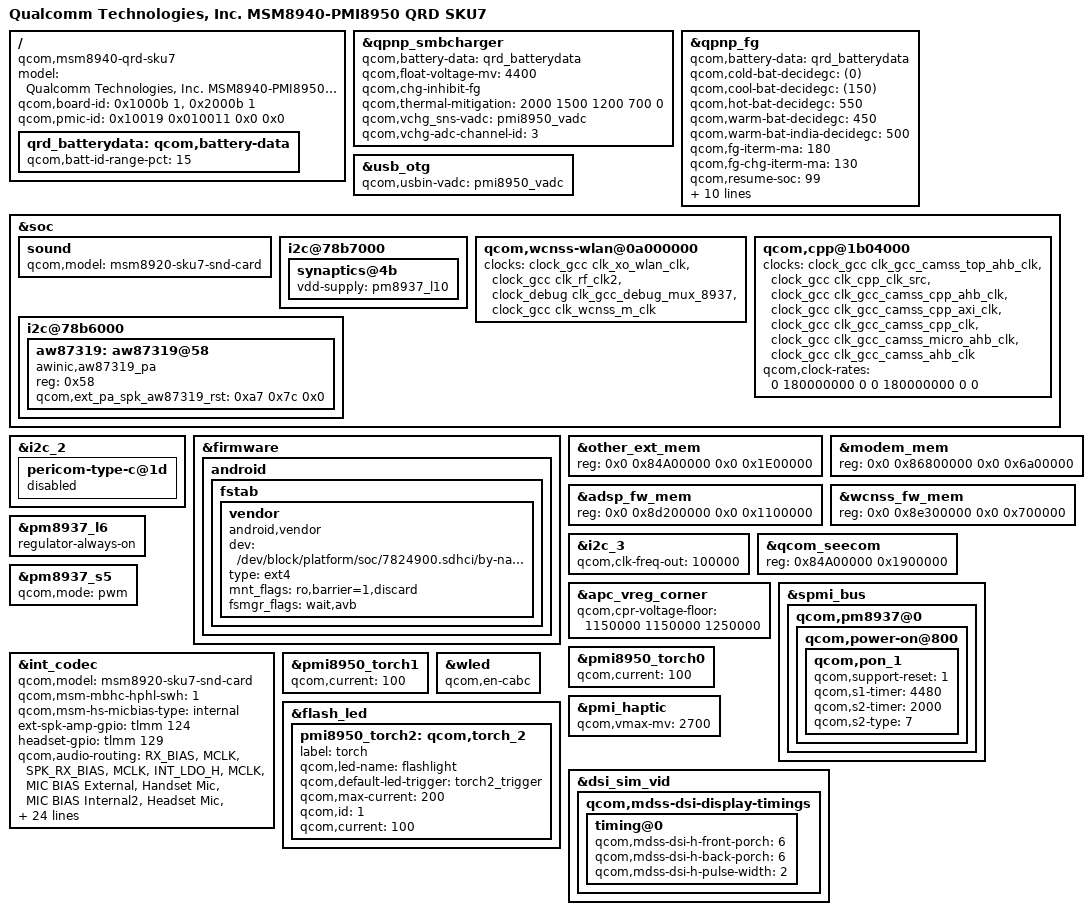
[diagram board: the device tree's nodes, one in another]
/*
 * Copyright (c) 2016, The Linux Foundation. All rights reserved.
 * Copyright (C) 2018 XiaoMi, Inc.
 *
 * This program is free software; you can redistribute it and/or modify
 * it under the terms of the GNU General Public License version 2 and
 * only version 2 as published by the Free Software Foundation.
 *
 * This program is distributed in the hope that it will be useful,
 * but WITHOUT ANY WARRANTY; without even the implied warranty of
 * MERCHANTABILITY or FITNESS FOR A PARTICULAR PURPOSE.  See the
 * GNU General Public License for more details.
 */

/dts-v1/;

#include "msm8940.dtsi"
#include "msm8937-pmi8950-qrd-sku1_S88536AA2.dtsi"
#include "msm8940-pinctrl.dtsi"

/ {
	model = "Qualcomm Technologies, Inc. MSM8940-PMI8950 QRD SKU7";
	compatible = "qcom,msm8940-qrd-sku7", "qcom,msm8940-qrd",
			"qcom,msm8940", "qcom,qrd";
	qcom,board-id= <0x1000b 1>, <0x2000b 1>;
	qcom,pmic-id = <0x10019 0x010011 0x0 0x0>;
};

/ {
	qrd_batterydata: qcom,battery-data {
		qcom,batt-id-range-pct = <15>;
		#include "batterydata-qrd-Desay-4v4-4100mah.dtsi"
		#include "batterydata-qrd-Atl-4v4-4100mah.dtsi"
		#include "batterydata-qrd-Coslight-4v4-4100mah.dtsi"
		#include "batterydata-qrd-Default-4v4-4100mah.dtsi"
	};
};

&qpnp_smbcharger { 
	qcom,battery-data = <&qrd_batterydata>;
	qcom,float-voltage-mv = <4400>;
	qcom,chg-inhibit-fg;
	qcom,thermal-mitigation = <2000 1500 1200 700 0>;
	status = "okay";
	qcom,vchg_sns-vadc = <&pmi8950_vadc>;
	qcom,vchg-adc-channel-id = <3>;

	/delete-property/ qcom,autoadjust-vfloat;
        /delete-property/ dpdm-supply;
};

&qpnp_fg { 
	qcom,battery-data = <&qrd_batterydata>;
	qcom,cold-bat-decidegc = <(0)>;
	qcom,cool-bat-decidegc = <(150)>;
	qcom,hot-bat-decidegc = <550>;
	qcom,warm-bat-decidegc = <450>;
	qcom,warm-bat-india-decidegc = <500>;
	qcom,fg-iterm-ma = <180>;
	qcom,fg-chg-iterm-ma = <130>;
	qcom,resume-soc = <99>;
	qcom,resume-soc-raw = <253>;
	qcom,vbat-estimate-diff-mv = <100>;
	qcom,fg-cutoff-voltage-mv = <3400>;
	qcom,fg-cc-cv-threshold-mv = <4390>;
	qcom,cl-max-increment-deciperc = <1>;
	qcom,cl-max-decrement-deciperc = <1>;
	qcom,fg-delta-soc = <1>;
	qcom,bad-battery-detection-enable;
	qcom,hold-soc-while-full;
	qcom,thermal-coefficients = [B7 85 B2 49 71 35];
};

&usb_otg {
	qcom,usbin-vadc = <&pmi8950_vadc>;
};
&soc {
	sound {
		qcom,model = "msm8920-sku7-snd-card";
	};

	i2c@78b7000 {
		synaptics@4b {
			vdd-supply = <&pm8937_l10>;
		};
	};
};

&i2c_2 {
	pericom-type-c@1d {
		status="disabled";
	};
};

&firmware{
	android {
		fstab{
			// Remove this line to boot oreo.
			/delete-node/ vendor;
			//This is for booting Treble pie
			 vendor {
                                        compatible = "android,vendor";
                                        dev = "/dev/block/platform/soc/7824900.sdhci/by-name/cust";
                                        type = "ext4";
                                        mnt_flags = "ro,barrier=1,discard";
                                        fsmgr_flags = "wait,avb";
                                        status = "ok";
                                };
		};
	};
};


/* 
 * =========================================
 * ==== DTS refactor v2 | msm8937.dtsi =====
 * =========================================
 */

// Reserved-memory regions
&other_ext_mem{
	reg = <0x0 0x84A00000 0x0 0x1E00000>;
};
&modem_mem{
	reg = <0x0 0x86800000 0x0 0x6a00000>;
};
&adsp_fw_mem{
	reg = <0x0 0x8d200000 0x0 0x1100000>;
};
&wcnss_fw_mem{
	reg = <0x0 0x8e300000 0x0 0x700000>;
};

// i2c_3 mods
&i2c_3{
	qcom,clk-freq-out = <100000>;
	status= "ok";
};

// wlan changes
&soc{
	qcom,wcnss-wlan@0a000000{
		clocks = <&clock_gcc clk_xo_wlan_clk>,
			 <&clock_gcc clk_rf_clk2>,
			 <&clock_debug clk_gcc_debug_mux_8937>,
			 <&clock_gcc clk_wcnss_m_clk>;
			 //<&clock_gcc clk_snoc_wcnss_a_clk>;
		clock-names = "xo", "rf_clk", "measure", "wcnss_debug";
				//"snoc_wcnss";
		/delete-property/ qcom,snoc-wcnss-clock-freq;
	};
	
};

// usb otg
&usb_otg{
	qcom,usbin-vadc = <&pmi8950_vadc>;
};

// qcom seecom
&qcom_seecom{
	reg = <0x84A00000 0x1900000>;
};

// msm8937-regulator.dtsi
&pm8937_l6{
	regulator-always-on;
};

&pm8937_s5{
	qcom,mode = "pwm";
};

&apc_vreg_corner{
	qcom,cpr-voltage-floor =   <1150000 1150000 1250000>;
	/delete-property/ qcom,cpr-enable;
};

//pm8937.dtsi
&spmi_bus {
        qcom,pm8937@0 {
                qcom,power-on@800 {
                        qcom,pon_1 {
				qcom,support-reset = <1>;
				qcom,s1-timer = <4480>;
				qcom,s2-timer = <2000>;
				qcom,s2-type = <7>;
                        };
		};
	};
};

&soc{
	qcom,cpp@1b04000 {
		clocks = /*<&clock_gcc clk_gcc_camss_ispif_ahb_clk>,*/			
			<&clock_gcc clk_gcc_camss_top_ahb_clk>,
			<&clock_gcc clk_cpp_clk_src>,
			<&clock_gcc clk_gcc_camss_cpp_ahb_clk>,
			<&clock_gcc clk_gcc_camss_cpp_axi_clk>,
			<&clock_gcc clk_gcc_camss_cpp_clk>,
			<&clock_gcc clk_gcc_camss_micro_ahb_clk>,
			<&clock_gcc clk_gcc_camss_ahb_clk>;
		clock-names = /*"ispif_ahb_clk",*/ 
			"camss_top_ahb_clk", "cpp_core_clk", "camss_vfe_cpp_ahb_clk",
			"camss_vfe_cpp_axi_clk", "camss_vfe_cpp_clk",
			"micro_iface_clk", "camss_ahb_clk";
		qcom,clock-rates = <0 180000000 0 0 180000000 0 0>;
	};
};

//msm8937-audio.dtsi
&int_codec{
	status = "okay";
	qcom,model = "msm8920-sku7-snd-card";
	qcom,msm-mbhc-hphl-swh = <1>;
	qcom,msm-hs-micbias-type = "internal";
	ext-spk-amp-gpio = <&tlmm 124 0>;
	headset-gpio = <&tlmm 129 0>;
	qcom,audio-routing =
			 "RX_BIAS", "MCLK", 
			 "SPK_RX_BIAS", "MCLK", 
			 "INT_LDO_H", "MCLK", 
			 "MIC BIAS External", 
			 "Handset Mic", "MIC BIAS Internal2", 
			 "Headset Mic", "MIC BIAS External", 
			 "Secondary Mic", "AMIC1", 
			 "MIC BIAS External", "AMIC2", 
			 "MIC BIAS Internal2", 
			 "AMIC3", "MIC BIAS External";
	asoc-platform-names = "msm-pcm-dsp.0", "msm-pcm-dsp.1", 
			"msm-pcm-dsp.2", "msm-voip-dsp", 
			"msm-pcm-voice", "msm-pcm-loopback", 
			"msm-compress-dsp", "msm-pcm-hostless", 
			"msm-pcm-afe", "msm-lsm-client", 
			"msm-pcm-routing", "msm-pcm-lpa";
	asoc-cpu-names = "msm-dai-q6-auxpcm.1", 
			"msm-dai-q6-mi2s.0", "msm-dai-q6-mi2s.1", 
			"msm-dai-q6-mi2s.2", "msm-dai-q6-mi2s.3", 
			"msm-dai-q6-mi2s.5", "msm-dai-q6-mi2s.6", 
			"msm-dai-q6-dev.16384", "msm-dai-q6-dev.16385", 
			"msm-dai-q6-dev.16386", "msm-dai-q6-dev.16387", 
			"msm-dai-q6-dev.16390", "msm-dai-q6-dev.16391", 
			"msm-dai-q6-dev.16392", "msm-dai-q6-dev.16393", 
			"msm-dai-q6-dev.12288", "msm-dai-q6-dev.12289", 
			"msm-dai-q6-dev.12292", "msm-dai-q6-dev.12293", 
			"msm-dai-q6-dev.224", "msm-dai-q6-dev.225", 
			"msm-dai-q6-dev.241", "msm-dai-q6-dev.240", 
			"msm-dai-q6-dev.32771", "msm-dai-q6-dev.32772", 
			"msm-dai-q6-dev.32773", "msm-dai-q6-dev.32770";
	qcom,cdc-us-euro-gpios;
	/delete-property/ asoc-codec;
	/delete-property/ asoc-codec-names;
};
&soc{
	i2c@78b6000 {
		aw87319: aw87319@58 {
			compatible = "awinic,aw87319_pa";
			reg = <0x58>;
			qcom,ext_pa_spk_aw87319_rst = <0xa7 0x7c 0x0>;
		};
	};
};

//pmi8950.dtsi
&pmi8950_torch0{
        qcom,current = <100>;
};

&pmi8950_torch1{
	qcom,current = <100>;
};

&wled{
	qcom,en-cabc;
};

&flash_led{
	pmi8950_torch2: qcom,torch_2 {
		label = "torch";
		qcom,led-name = "flashlight";
		qcom,default-led-trigger = 
				"torch2_trigger";
		qcom,max-current = <200>;
		qcom,id = <1>;
		qcom,current = <100>;
	};
};

&pmi_haptic{
	qcom,vmax-mv = <2700>;
	/delete-property/ qcom,en-brake;
};

//dsi-panel-sim-video.dtsi
&dsi_sim_vid {
	qcom,mdss-dsi-display-timings {
        	timing@0{
                	qcom,mdss-dsi-h-front-porch = <6>;
                        qcom,mdss-dsi-h-back-porch = <6>;
                        qcom,mdss-dsi-h-pulse-width = <2>;
		};
	};
};
